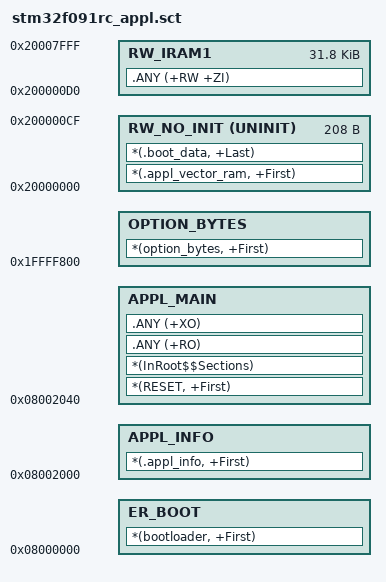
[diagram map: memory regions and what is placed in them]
; *************************************************************
; *** Scatter-Loading Description File for application      ***
; *************************************************************


LR_APPL_INFO 0x08002000 0x00000040
{
  APPL_INFO +0
  {
    *(.appl_info, +First)
  }
}

LR_APPL_MAIN 0x08002040 0x0003ffc0
{
  APPL_MAIN 0x08002040
  {
    *(RESET, +First)
    *(InRoot$$Sections)
    .ANY (+RO)
    .ANY (+XO)
  }

  RW_NO_INIT 0x20000000 UNINIT 0xd0
  {
    *(.appl_vector_ram, +First)
    *(.boot_data, +Last)
  }  

  RW_IRAM1 0x200000d0 0x00007f30
  {
   .ANY (+RW +ZI)
  }
}

LR_BOOT 0x08000000 0x00002000
{
  ER_BOOT +0
  {
    *(bootloader, +First)
  }
}

; When using Segger tools the option bytes must be located at
; 0x06000000. Keil and ST-Link/V2 are able to handle option bytes
; located at 0x1ffff800.
; 
; From the Segger Wiki:
; > Note: The address 0x06000000 is a virtual address only. The option
; > bytes are originally located at address 0x1FFFF800. The remap from
; > 0x06000000 to 0x1FFFF800 is done automatically by J-Flash.

LR_OPTION_BYTES 0x1FFFF800 16
{
  OPTION_BYTES +0
  {
    *(option_bytes, +First)
  }
}

